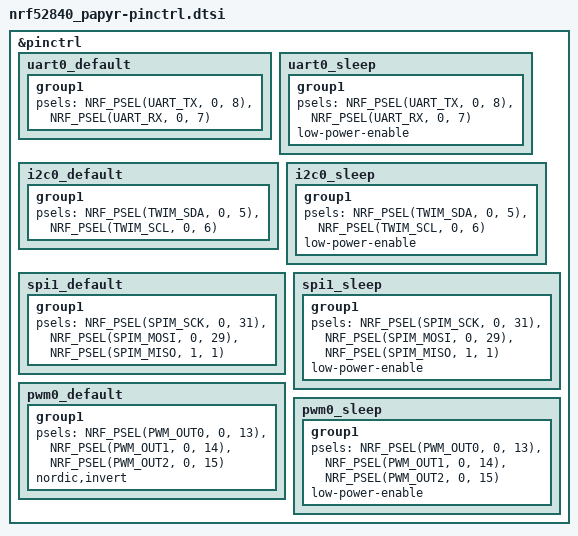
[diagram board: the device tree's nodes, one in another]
/*
 * Copyright (c) 2022 Nordic Semiconductor
 * SPDX-License-Identifier: Apache-2.0
 */

&pinctrl {
	uart0_default: uart0_default {
		group1 {
			psels = <NRF_PSEL(UART_TX, 0, 8)>,
				<NRF_PSEL(UART_RX, 0, 7)>;
		};
	};

	uart0_sleep: uart0_sleep {
		group1 {
			psels = <NRF_PSEL(UART_TX, 0, 8)>,
				<NRF_PSEL(UART_RX, 0, 7)>;
			low-power-enable;
		};
	};

	i2c0_default: i2c0_default {
		group1 {
			psels = <NRF_PSEL(TWIM_SDA, 0, 5)>,
				<NRF_PSEL(TWIM_SCL, 0, 6)>;
		};
	};

	i2c0_sleep: i2c0_sleep {
		group1 {
			psels = <NRF_PSEL(TWIM_SDA, 0, 5)>,
				<NRF_PSEL(TWIM_SCL, 0, 6)>;
			low-power-enable;
		};
	};

	spi1_default: spi1_default {
		group1 {
			psels = <NRF_PSEL(SPIM_SCK, 0, 31)>,
				<NRF_PSEL(SPIM_MOSI, 0, 29)>,
				<NRF_PSEL(SPIM_MISO, 1, 1)>;
		};
	};

	spi1_sleep: spi1_sleep {
		group1 {
			psels = <NRF_PSEL(SPIM_SCK, 0, 31)>,
				<NRF_PSEL(SPIM_MOSI, 0, 29)>,
				<NRF_PSEL(SPIM_MISO, 1, 1)>;
			low-power-enable;
		};
	};

	pwm0_default: pwm0_default {
		group1 {
			psels = <NRF_PSEL(PWM_OUT0, 0, 13)>,
				<NRF_PSEL(PWM_OUT1, 0, 14)>,
				<NRF_PSEL(PWM_OUT2, 0, 15)>;
			nordic,invert;
		};
	};

	pwm0_sleep: pwm0_sleep {
		group1 {
			psels = <NRF_PSEL(PWM_OUT0, 0, 13)>,
				<NRF_PSEL(PWM_OUT1, 0, 14)>,
				<NRF_PSEL(PWM_OUT2, 0, 15)>;
			low-power-enable;
		};
	};

};
